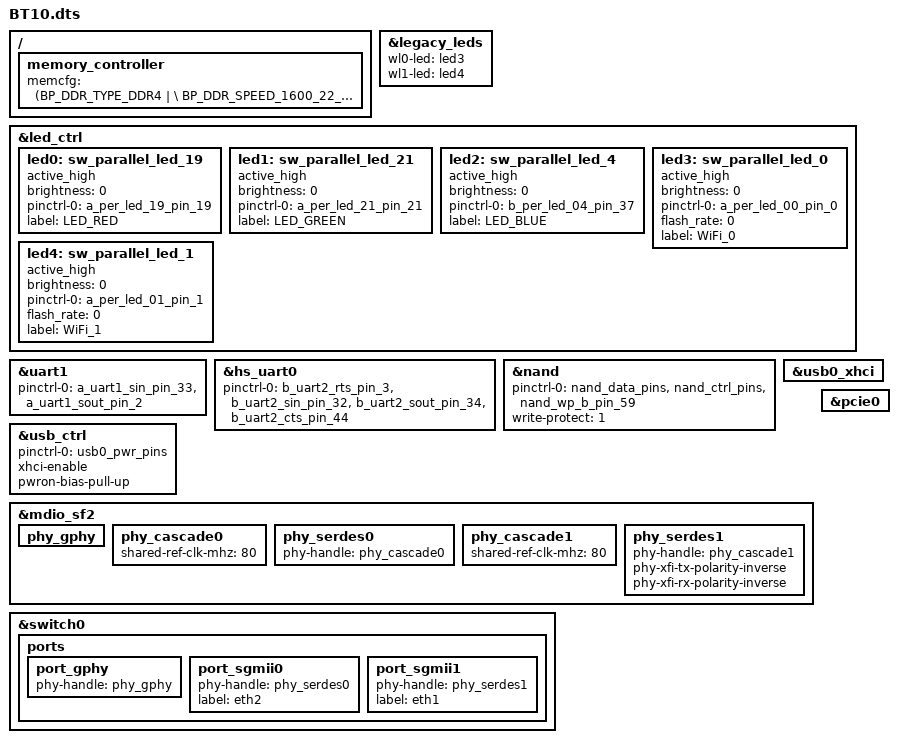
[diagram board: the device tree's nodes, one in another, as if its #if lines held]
#include "6766.dtsi"

/ {
    memory_controller {
        memcfg = <(BP_DDR_TYPE_DDR4       | \
            BP_DDR_SPEED_1600_22_22_22    | \
            BP_DDR_TOTAL_SIZE_2048MB      | \
            BP_DDR_DEVICE_WIDTH_16        | \
            BP_DDR_TOTAL_WIDTH_16BIT      | \
            BP_DDR_6766_DEFAULT           | \
            BP_DDR_CONFIG_DEBUG)>;
    };

/* remove mark if need
	buttons {
		compatible = "brcm,buttons";

		reset_button {
			ext_irq = <&bca_extintr 18 GPIO_ACTIVE_LOW (BCA_EXTINTR_TYPE_LOW_LEVEL | BCA_EXTINTR_TYPE_SENSE_EDGE)>;
			press {
				print = "Button Press -- Hold for 5s to do restore to default";
			};
			hold {
				rst_to_dflt = <5>;
			};
			release {
				reset = <0>;
			};
		};

		ses_button {
			ext_irq = <&bca_extintr 6 GPIO_ACTIVE_LOW (BCA_EXTINTR_TYPE_LOW_LEVEL | BCA_EXTINTR_TYPE_SENSE_EDGE)>;
			release {
				ses_short_period = <0>;
				ses_long_period = <3>;
			};
		};
	};
*/
};

&legacy_leds {
    wl0-led = <&led3>;
    wl1-led = <&led4>;
};

&led_ctrl {
    pinctrl-names = "default";

    /* LED_RED */
    led0: sw_parallel_led_19 {
        active_high;
        brightness = <0>;
        pinctrl-0 = <&a_per_led_19_pin_19>;
        status = "okay";
        label = "LED_RED";
    };
    /* LED_GREEN */
    led1: sw_parallel_led_21 {
        active_high;
        brightness = <0>;
        pinctrl-0 = <&a_per_led_21_pin_21>;
        status = "okay";
        label = "LED_GREEN";
    };
    /* LED_BLUE */
    led2: sw_parallel_led_4 {
        active_high;
        brightness = <0>;
        pinctrl-0 = <&b_per_led_04_pin_37>;
        status = "okay";
        label = "LED_BLUE";
    };

    led3: sw_parallel_led_0 {
        active_high;
        brightness = <0>;
        pinctrl-0 = <&a_per_led_00_pin_0>;
        flash_rate = <0>;
        status = "okay";
        label = "WiFi_0";
    };
    
    led4: sw_parallel_led_1 {
        active_high;
        brightness = <0>;
        pinctrl-0 = <&a_per_led_01_pin_1>;
        flash_rate = <0>;
        status = "okay";
        label = "WiFi_1";
    };
};

&uart1 {
	pinctrl-names = "default";
	pinctrl-0 = <&a_uart1_sin_pin_33 &a_uart1_sout_pin_2>;
	status = "okay";
};

&hs_uart0 {
	pinctrl-0 = <&b_uart2_rts_pin_3 &b_uart2_sin_pin_32 &b_uart2_sout_pin_34 &b_uart2_cts_pin_44>;
	pinctrl-names = "default";
	status = "okay";
};

&nand {
	pinctrl-0 = <&nand_data_pins &nand_ctrl_pins &nand_wp_b_pin_59>;
	write-protect = <1>;
	status = "okay";
};

&usb_ctrl {
    pinctrl-names="default";
    pinctrl-0 = <&usb0_pwr_pins>;
    status = "okay";
    xhci-enable;
    pwron-bias-pull-up;
};

&usb0_xhci {
    status = "okay";
};

&mdio_sf2 {
	/* Port PHY mapping:
	        port_imp -8#0- port_gphy <----> phy_gphy
	                  # 5- port_sgmii0 <--> phy_serdes0 - phy_cascade0
	                  ##6- port_sgmii1 <--> phy_serdes1 - phy_cascade1
	 */
	phy_gphy {
		status = "okay";
	};

	phy_cascade0 {
		shared-ref-clk-mhz = <80>;
		status = "okay";
	};

	phy_serdes0 {
		phy-handle = <&phy_cascade0>;
		status = "okay";
	};

	phy_cascade1 {
		shared-ref-clk-mhz = <80>;
		status = "okay";
	};

	phy_serdes1 {
		phy-handle = <&phy_cascade1>;
		phy-xfi-tx-polarity-inverse;
		phy-xfi-rx-polarity-inverse;
		status = "okay";
	};
};

&switch0 {

	ports {
		port_gphy {
			phy-handle = <&phy_gphy>;
			status = "okay";
		};

		port_sgmii0 {
			phy-handle = <&phy_serdes0>;
			status = "okay";
			label = "eth2";
		};

		port_sgmii1 {
			phy-handle = <&phy_serdes1>;
			status = "okay";
			label = "eth1";
		};
	};
};

#if defined(CONFIG_BCM_PCIE_HCD) || defined(CONFIG_BCM_PCIE_HCD_MODULE)
/**********************************************************************/
/* GPIO: Add one define per GPIO (individual or shared) regulator     */
/*       - Skip if no GPIO regulators in use                          */
/**********************************************************************/
#define PCIE0_REG_GPIO    15    /* PCIE0_PWR_CTRL for vreg_pcie0 node */

#include "../bcm_wlan_regulator.dtsi"

/**********************************************************************/
/* Shared: Add brcm,supply-names = "vreg-pcieX" for shared PCIe nodes */
/*         - Skip if not using shared GPIO regulators                 */
/**********************************************************************/

/**********************************************************************/
/* PCIe: Add status = "okay" for each PCIe slots of this boiard       */
/*       - Skip if this is a derivative board (already done in base)  */
/**********************************************************************/
&pcie0 {
	status = "okay";
};
#endif //#if defined(CONFIG_BCM_PCIE_HCD) || defined(CONFIG_BCM_PCIE_HCD_MODULE)
